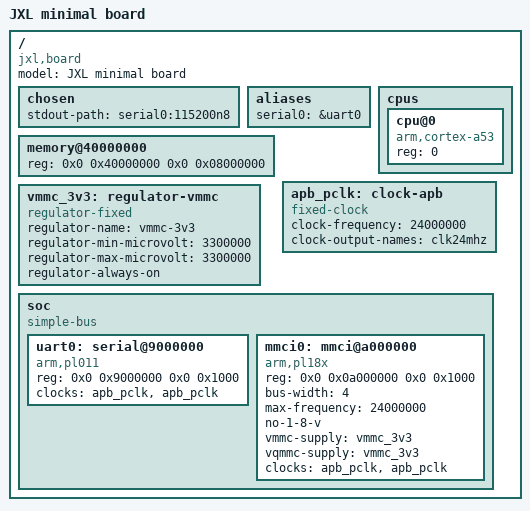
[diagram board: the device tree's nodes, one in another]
// SPDX-License-Identifier: GPL-2.0-or-later
/dts-v1/;

/ {
	#address-cells = <2>;
	#size-cells = <2>;
	model = "JXL minimal board";
	compatible = "jxl,board";

	chosen {
		stdout-path = "serial0:115200n8";
	};

	aliases {
		serial0 = &uart0;
	};

	cpus {
		#address-cells = <1>;
		#size-cells = <0>;

		cpu@0 {
			device_type = "cpu";
			compatible = "arm,cortex-a53";
			reg = <0>;
		};
	};

	memory@40000000 {
		device_type = "memory";
		reg = <0x0 0x40000000 0x0 0x08000000>;
	};

	apb_pclk: clock-apb {
		compatible = "fixed-clock";
		#clock-cells = <0>;
		clock-frequency = <24000000>;
		clock-output-names = "clk24mhz";
	};

	vmmc_3v3: regulator-vmmc {
		compatible = "regulator-fixed";
		regulator-name = "vmmc-3v3";
		regulator-min-microvolt = <3300000>;
		regulator-max-microvolt = <3300000>;
		regulator-always-on;
	};

	soc {
		compatible = "simple-bus";
		#address-cells = <2>;
		#size-cells = <2>;
		ranges;

		uart0: serial@9000000 {
			compatible = "arm,pl011", "arm,primecell";
			reg = <0x0 0x9000000 0x0 0x1000>;
			clocks = <&apb_pclk>, <&apb_pclk>;
			clock-names = "uartclk", "apb_pclk";
		};

		mmci0: mmci@a000000 {
			compatible = "arm,pl18x", "arm,primecell";
			reg = <0x0 0x0a000000 0x0 0x1000>;
			bus-width = <4>;
			max-frequency = <24000000>;
			no-1-8-v;
			vmmc-supply = <&vmmc_3v3>;
			vqmmc-supply = <&vmmc_3v3>;
			clocks = <&apb_pclk>, <&apb_pclk>;
			clock-names = "mclk", "apb_pclk";
		};
	};
};
